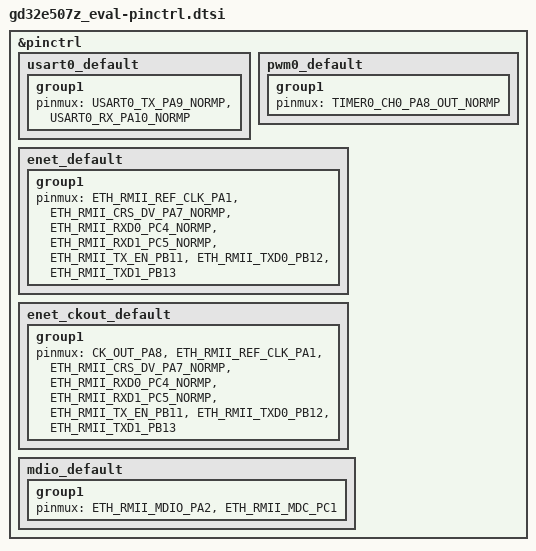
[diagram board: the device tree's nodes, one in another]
/*
 * Copyright (c) 2022, Teslabs Engineering S.L.
 * SPDX-License-Identifier: Apache-2.0
 */

#include <dt-bindings/pinctrl/gd32e507z(e-c)xx-pinctrl.h>

&pinctrl {
	usart0_default: usart0_default {
		group1 {
			pinmux = <USART0_TX_PA9_NORMP>, <USART0_RX_PA10_NORMP>;
		};
	};

	pwm0_default: pwm0_default {
		group1 {
			pinmux = <TIMER0_CH0_PA8_OUT_NORMP>;
		};
	};

	enet_default: enet_default {
		group1 {
			pinmux = <ETH_RMII_REF_CLK_PA1>,
				 <ETH_RMII_CRS_DV_PA7_NORMP>,
				 <ETH_RMII_RXD0_PC4_NORMP>,
				 <ETH_RMII_RXD1_PC5_NORMP>,
				 <ETH_RMII_TX_EN_PB11>, <ETH_RMII_TXD0_PB12>,
				 <ETH_RMII_TXD1_PB13>;
		};
	};

	enet_ckout_default: enet_ckout_default {
		group1 {
			pinmux = <CK_OUT_PA8>, <ETH_RMII_REF_CLK_PA1>,
				 <ETH_RMII_CRS_DV_PA7_NORMP>,
				 <ETH_RMII_RXD0_PC4_NORMP>,
				 <ETH_RMII_RXD1_PC5_NORMP>,
				 <ETH_RMII_TX_EN_PB11>, <ETH_RMII_TXD0_PB12>,
				 <ETH_RMII_TXD1_PB13>;
		};
	};

	mdio_default: mdio_default {
		group1 {
			pinmux = <ETH_RMII_MDIO_PA2>, <ETH_RMII_MDC_PC1>;
		};
	};
};
